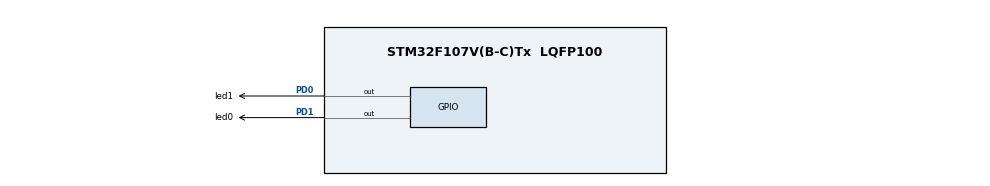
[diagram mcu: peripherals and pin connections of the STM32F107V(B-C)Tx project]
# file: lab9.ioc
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Mcu.Family=STM32F1
Mcu.Name=STM32F107V(B-C)Tx
Mcu.Package=LQFP100
NVIC.PriorityGroup=NVIC_PRIORITYGROUP_4
NVIC.TIM2_IRQn=true\:0\:0\:false\:false\:true\:true\:true\:true
NVIC.TIM3_IRQn=true\:0\:0\:false\:false\:true\:true\:true\:true
PA13.Mode=Serial_Wire
PA13.Signal=SYS_JTMS-SWDIO
PA14.Mode=Serial_Wire
PA14.Signal=SYS_JTCK-SWCLK
PD0.GPIO_Label=led1
PD0.Signal=GPIO_Output
PD1.GPIO_Label=led0
PD1.Signal=GPIO_Output
ProjectManager.HeapSize=0x200
ProjectManager.StackSize=0x400
ProjectManager.TargetToolchain=MDK-ARM V5.32
RCC.USBFreq_Value=10666666.666666666
TIM2.Period=63999
TIM2.Prescaler=124
TIM3.Prescaler=124
VP_TIM2_VS_ClockSourceINT.Mode=Internal
VP_TIM3_VS_ClockSourceINT.Mode=Internal
board=custom

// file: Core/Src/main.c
/* USER CODE BEGIN Header */
/**
  ******************************************************************************
  * @file           : main.c
  * @brief          : Main program body
  ******************************************************************************
  * @attention
  *
  * Copyright (c) 2025 STMicroelectronics.
  * All rights reserved.
  *
  * This software is licensed under terms that can be found in the LICENSE file
  * in the root directory of this software component.
  * If no LICENSE file comes with this software, it is provided AS-IS.
  *
  ******************************************************************************
  */
/* USER CODE END Header */
#include "main.h"

TIM_HandleTypeDef htim2;
TIM_HandleTypeDef htim3;

void SystemClock_Config(void);
static void MX_GPIO_Init(void);
static void MX_TIM2_Init(void);
static void MX_TIM3_Init(void);

/* USER CODE BEGIN 0 */
int timer_value=0;
/* USER CODE END 0 */

int main(void)
{

  /* MCU Configuration--------------------------------------------------------*/

  /* Reset of all peripherals, Initializes the Flash interface and the Systick. */
  HAL_Init();

  /* Configure the system clock */
  SystemClock_Config();

  /* Initialize all configured peripherals */
  MX_GPIO_Init();
  MX_TIM2_Init();
  MX_TIM3_Init();
  /* USER CODE BEGIN 2 */
	HAL_TIM_Base_Start_IT(&htim2);
	HAL_Delay(500);
	HAL_TIM_Base_Start_IT(&htim3);

	HAL_GPIO_WritePin(led0_GPIO_Port, led0_Pin, GPIO_PIN_RESET);
	HAL_GPIO_WritePin(led1_GPIO_Port, led1_Pin, GPIO_PIN_RESET);
  /* USER CODE END 2 */

  /* Infinite loop */
  while (1)
  {

  }
}

void SystemClock_Config(void)
{
  RCC_OscInitTypeDef RCC_OscInitStruct = {0};
  RCC_ClkInitTypeDef RCC_ClkInitStruct = {0};

  /** Initializes the RCC Oscillators according to the specified parameters
  * in the RCC_OscInitTypeDef structure.
  */
  RCC_OscInitStruct.OscillatorType = RCC_OSCILLATORTYPE_HSI;
  RCC_OscInitStruct.HSIState = RCC_HSI_ON;
  RCC_OscInitStruct.HSICalibrationValue = RCC_HSICALIBRATION_DEFAULT;
  RCC_OscInitStruct.PLL.PLLState = RCC_PLL_NONE;
  RCC_OscInitStruct.PLL2.PLL2State = RCC_PLL_NONE;
  if (HAL_RCC_OscConfig(&RCC_OscInitStruct) != HAL_OK)
  {
    Error_Handler();
  }

  /** Initializes the CPU, AHB and APB buses clocks
  */
  RCC_ClkInitStruct.ClockType = RCC_CLOCKTYPE_HCLK|RCC_CLOCKTYPE_SYSCLK
                              |RCC_CLOCKTYPE_PCLK1|RCC_CLOCKTYPE_PCLK2;
  RCC_ClkInitStruct.SYSCLKSource = RCC_SYSCLKSOURCE_HSI;
  RCC_ClkInitStruct.AHBCLKDivider = RCC_SYSCLK_DIV1;
  RCC_ClkInitStruct.APB1CLKDivider = RCC_HCLK_DIV1;
  RCC_ClkInitStruct.APB2CLKDivider = RCC_HCLK_DIV1;

  if (HAL_RCC_ClockConfig(&RCC_ClkInitStruct, FLASH_LATENCY_0) != HAL_OK)
  {
    Error_Handler();
  }

  /** Configure the Systick interrupt time
  */
  __HAL_RCC_PLLI2S_ENABLE();
}

static void MX_TIM2_Init(void)
{

  TIM_ClockConfigTypeDef sClockSourceConfig = {0};
  TIM_MasterConfigTypeDef sMasterConfig = {0};

  htim2.Instance = TIM2;
  htim2.Init.Prescaler = 124;
  htim2.Init.CounterMode = TIM_COUNTERMODE_UP;
  htim2.Init.Period = 63999;
  htim2.Init.ClockDivision = TIM_CLOCKDIVISION_DIV1;
  htim2.Init.AutoReloadPreload = TIM_AUTORELOAD_PRELOAD_DISABLE;
  if (HAL_TIM_Base_Init(&htim2) != HAL_OK)
  {
    Error_Handler();
  }
  sClockSourceConfig.ClockSource = TIM_CLOCKSOURCE_INTERNAL;
  if (HAL_TIM_ConfigClockSource(&htim2, &sClockSourceConfig) != HAL_OK)
  {
    Error_Handler();
  }
  sMasterConfig.MasterOutputTrigger = TIM_TRGO_RESET;
  sMasterConfig.MasterSlaveMode = TIM_MASTERSLAVEMODE_DISABLE;
  if (HAL_TIMEx_MasterConfigSynchronization(&htim2, &sMasterConfig) != HAL_OK)
  {
    Error_Handler();
  }

}

static void MX_TIM3_Init(void)
{

  TIM_ClockConfigTypeDef sClockSourceConfig = {0};
  TIM_MasterConfigTypeDef sMasterConfig = {0};

  htim3.Instance = TIM3;
  htim3.Init.Prescaler = 124;
  htim3.Init.CounterMode = TIM_COUNTERMODE_UP;
  htim3.Init.Period = 65535;
  htim3.Init.ClockDivision = TIM_CLOCKDIVISION_DIV1;
  htim3.Init.AutoReloadPreload = TIM_AUTORELOAD_PRELOAD_DISABLE;
  if (HAL_TIM_Base_Init(&htim3) != HAL_OK)
  {
    Error_Handler();
  }
  sClockSourceConfig.ClockSource = TIM_CLOCKSOURCE_INTERNAL;
  if (HAL_TIM_ConfigClockSource(&htim3, &sClockSourceConfig) != HAL_OK)
  {
    Error_Handler();
  }
  sMasterConfig.MasterOutputTrigger = TIM_TRGO_RESET;
  sMasterConfig.MasterSlaveMode = TIM_MASTERSLAVEMODE_DISABLE;
  if (HAL_TIMEx_MasterConfigSynchronization(&htim3, &sMasterConfig) != HAL_OK)
  {
    Error_Handler();
  }

}

static void MX_GPIO_Init(void)
{
  GPIO_InitTypeDef GPIO_InitStruct = {0};

  /* GPIO Ports Clock Enable */
  __HAL_RCC_GPIOA_CLK_ENABLE();
  __HAL_RCC_GPIOD_CLK_ENABLE();

  /*Configure GPIO pin Output Level */
  HAL_GPIO_WritePin(GPIOD, led1_Pin|led0_Pin, GPIO_PIN_RESET);

  /*Configure GPIO pins : led1_Pin led0_Pin */
  GPIO_InitStruct.Pin = led1_Pin|led0_Pin;
  GPIO_InitStruct.Mode = GPIO_MODE_OUTPUT_PP;
  GPIO_InitStruct.Pull = GPIO_NOPULL;
  GPIO_InitStruct.Speed = GPIO_SPEED_FREQ_LOW;
  HAL_GPIO_Init(GPIOD, &GPIO_InitStruct);

}

/* USER CODE BEGIN 4 */

void HAL_TIM_PeriodElapsedCallback(TIM_HandleTypeDef *htim)
{
  /* Prevent unused argument(s) compilation warning */
  UNUSED(htim);
	// if (htim->Instance == htim2.instance); // For every timer interrup this function runs so that you need to emphasize which one you want to work
	if (htim->Instance == htim2.Instance){
		HAL_GPIO_TogglePin(led0_GPIO_Port, led0_Pin);
	}

	if (htim->Instance == htim3.Instance){
		HAL_GPIO_TogglePin(led1_GPIO_Port, led1_Pin);
	}

  /* NOTE : This function should not be modified, when the callback is needed,
            the HAL_TIM_PeriodElapsedCallback could be implemented in the user file
   */
}

/* USER CODE END 4 */

void Error_Handler(void)
{
  __disable_irq();
  while (1)
  {
  }
}
